# RA6M2 register map
Vendor: Renesas Electronics Corporation; Series: RA6; File version: 1.1
CPU: CM4 r0p1, little endian, MPU, FPU, VTOR, 4 interrupt priority bits
Registers are 8-bit, read-write, reset 0x0 unless marked. A register's access mark holds for its fields unless they carry their own. Offsets are from the block's base; [hi:lo] are bit positions; 'fields as' and 'values as' point back to an identical list.

## SPMON — CPU Stack Pointer Monitor
Base 0x40000D00
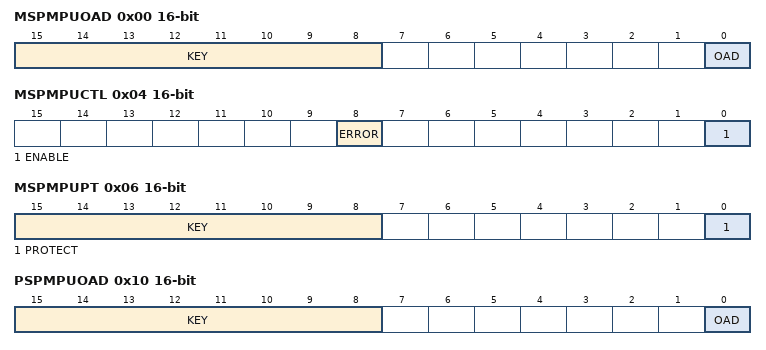
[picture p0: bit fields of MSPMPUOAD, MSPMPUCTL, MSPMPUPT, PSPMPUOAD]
0x00 MSPMPUOAD 16-bit — Stack Pointer Monitor Operation After Detection Register
  [15:8] KEY wo — Write Keyword The data written to these bits are not stored.
    165=Writing to the OAD bit is valid, when the KEY bits are written 0xA5; other=others (Writing to the OAD bit is invalid.)
  [0] OAD — Operation after detection
    1=Internal reset; 0=Non-maskable interrupt
0x04 MSPMPUCTL 16-bit (reset mask 0xFEFF) — Stack Pointer Monitor Access Control Register
  [8] ERROR — Stack Pointer Monitor Error Flag
    0=No stack pointer overflow and underflow occurred; 1=Stack pointer overflow or underflow occurred
  [0] ENABLE — Stack Pointer Monitor Enable
    0=Stack pointer monitor disabled; 1=Stack pointer monitor enabled
0x06 MSPMPUPT 16-bit — Stack Pointer Monitor Protection Register
  [15:8] KEY wo — Write Keyword The data written to these bits are not stored.
    165=Writing to the PROTECT bit is valid, when the KEY bits are written 0xA5; other=others (Writing to the PROTECT bit is invalid.)
  [0] PROTECT — Protection of register (MSPMPUAC, MSPMPUSA and MSPMPUSE)
    0=Stack Pointer Monitor register writing is possible; 1=Stack Pointer Monitor register writing is protected
0x08 MSPMPUSA 32-bit (reset mask 0x3) — Main Stack Pointer Monitor Start Address Register
  [31:0] MSPMPUSA range 0x1FF00000..0x200FFFFC — Region start address register Address where the region starts, for use in region determination.NOTE: Range: 0x1FF00000-0x200FFFFC The low-order 2 bits are fixed to 0.
0x0C MSPMPUEA 32-bit reset 0x3 (reset mask 0x3) — Main Stack Pointer Monitor End Address Register
  [31:0] MSPMPUEA range 0x1FF00003..0x200FFFFF — Region end address register Address where the region starts, for use in region determination.NOTE: Range: 0x1FF00003-0x200FFFFF The low-order 2 bits are fixed to 1.
0x10 PSPMPUOAD 16-bit — Stack Pointer Monitor Operation After Detection Register
  fields as MSPMPUOAD
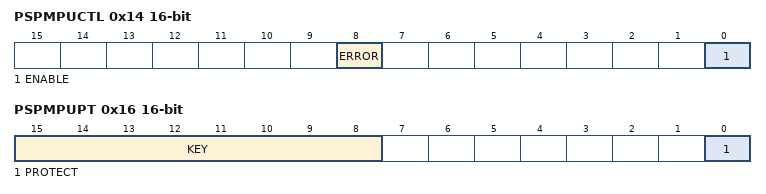
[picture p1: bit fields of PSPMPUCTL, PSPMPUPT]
0x14 PSPMPUCTL 16-bit (reset mask 0xFEFF) — Stack Pointer Monitor Access Control Register
  fields as MSPMPUCTL
0x16 PSPMPUPT 16-bit — Stack Pointer Monitor Protection Register
  [15:8] KEY wo — Write Keyword The data written to these bits are not stored.
    values as MSPMPUPT.KEY
  [0] PROTECT — Protection of register (PSPMPUAC, PSPMPUSA and PSPMPUSE)
    values as MSPMPUPT.PROTECT
0x18 PSPMPUSA 32-bit (reset mask 0x3) — Process Stack Pointer Monitor Start Address Register
  [31:0] PSPMPUSA range 0x1FF00000..0x200FFFFC — Region start address register Address where the region starts, for use in region determination.NOTE: Range: 0x1FF00000-0x200FFFFC The low-order 2 bits are fixed to 0.
0x1C PSPMPUEA 32-bit reset 0x3 (reset mask 0x3) — Process Stack Pointer Monitor End Address Register
  [31:0] PSPMPUEA range 0x1FF00003..0x200FFFFF — Region end address register Address where the region starts, for use in region determination.NOTE: Range: 0x1FF00003-0x200FFFFF The low-order 2 bits are fixed to 1.

## SRAM — SRAM Control
Base 0x40002000
0x00 PARIOAD — SRAM Parity Error Operation After Detection Register
  [0] OAD — Operation after Detection
    0=Non-maskable interrupt; 1=Reset
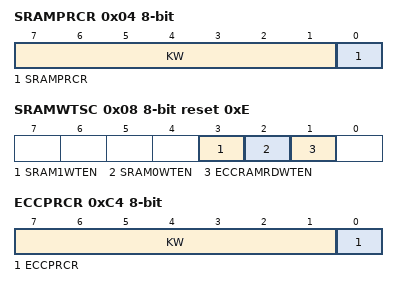
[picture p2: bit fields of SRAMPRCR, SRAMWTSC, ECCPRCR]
0x04 SRAMPRCR — SRAM Protection Register
  [7:1] KW wo — Write Key Code
    120=Writing to the RAMPRCR bit is valid, when the KEY bits are written 1111000b; other=others (Writing to the RAMPRCR bit is invalid.)
  [0] SRAMPRCR — Register Write Control
    0=Disable writes to protected registers; 1=Enable writes to protected registers
0x08 SRAMWTSC reset 0xE — RAM Wait State Control Register
  [3] SRAM1WTEN — SRAM1 Wait Enable
    0=Not add wait state in read access cycle to SRAM1; 1=Add wait state in read access cycle to SRAM1
  [2] SRAM0WTEN — SRAM0 Wait Enable
    0=Not add wait state in read access cycle to SRAM0; 1=Add wait state in read access cycle to SRAM0
  [1] ECCRAMRDWTEN — ECCRAM Read wait enable
    0=Not add wait state in read access cycle to SRAM0 (ECC area); 1=Add wait state in read access cycle to SRAM0 (ECC area)
0xC0 ECCMODE — ECCRAM Operating Mode Control Register
  [1:0] ECCMOD — ECC Operating Mode Select
    0=Disable ECC function; 1=Setting prohibited; 2=Enable ECC function without error checking; 3=Enable ECC function with error checking
0xC1 ECC2STS — ECCRAM 2-Bit Error Status Register
  [0] ECC2ERR write-0-clears read-modifies — ECC 2-Bit Error Status
    0=No 2-bit ECC error occurred; 1=2-bit ECC error occurred
0xC2 ECC1STSEN — ECCRAM 1-Bit Error Information Update Enable Register
  [0] E1STSEN — ECC 1-Bit Error Information Update Enable
    0=Disables updating of the 1-bit ECC error information; 1=Enables updating of the 1-bit ECC error information
0xC3 ECC1STS — ECCRAM 1-Bit Error Status Register
  [0] ECC1ERR write-0-clears read-modifies — ECC 1-Bit Error Status
    0=No 1-bit ECC error occurred; 1=1-bit ECC error occurred
0xC4 ECCPRCR — ECCRAM Protection Register
  [7:1] KW wo — Write Key Code
    120=Writing to the ECCRAMPRCR bit is valid, when the KEY bits are written 1111000b; other=others (Writing to the ECCRAMPRCR bit is invalid.)
  [0] ECCPRCR — ECCRAMETST Register Write Control
    values as SRAMPRCR.SRAMPRCR
0xD4 ECCETST — ECC Test Control Register
  [0] TSTBYP — ECC Bypass Select
    0=ECC bypass disabled; 1=ECC bypass enabled
0xD8 ECCOAD — RAM ECC Error Operation After Detection Register
  [0] OAD — Operation after Detection
    0=Non maskable interrupt; 1=Internal reset
